# D1H.pdf register map
Vendor: Allwinner; Series: D1H.pdf; File version: 0.1
CPU: XuanTie C906 RISC-V CPU 0, little endian, MPU, FPU, double-precision FPU, 0 interrupt priority bits
Registers are 32-bit, read-write, reset 0x0 unless marked. A register's access mark holds for its fields unless they carry their own. Offsets are from the block's base; [hi:lo] are bit positions; {n}, {i} and the like mark numbered series; 'fields as' and 'values as' point back to an identical list.

## IOMMU
Base 0x02010000
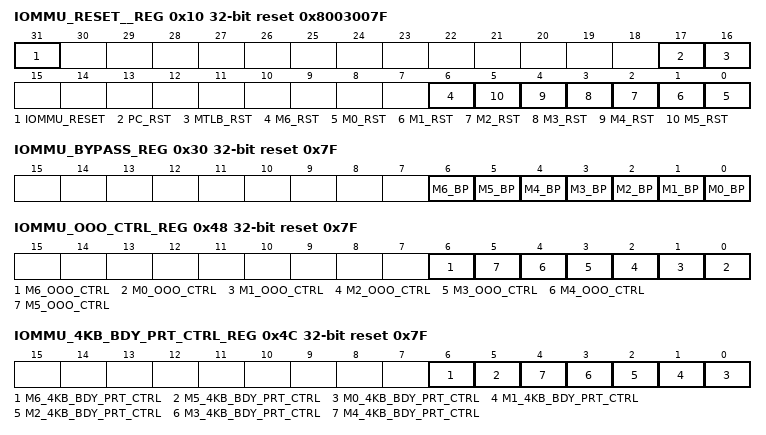
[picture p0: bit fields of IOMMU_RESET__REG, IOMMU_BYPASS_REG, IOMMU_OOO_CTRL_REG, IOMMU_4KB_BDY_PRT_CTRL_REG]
0x10 IOMMU_RESET__REG reset 0x8003007F
  [31] IOMMU_RESET — IOMMU Software Reset Switch 0: Set reset signal 1: Release reset signal Before IOMMU software reset operation, ensure IOMMU never be opened; or all bus operations are completed; or DRAM and the peripherals have opened the corresponding switch, for shielding the effects of IOMMU reset.
    0=Set (Set reset signal); 1=Release reset signal Before IOMMU software reset operation, ensure IOMMU never be opened; or all bus operations are completed; or DRAM and the peripherals have opened the corresponding switch, for shielding the effects of IOMMU reset
  [17] PC_RST — PTW Cache Reset PTW Cache address convert lane software reset switch. 0: Set reset signal 1: Release reset signal When PTW Cache occurs abnormal, the bit is used to reset PTW Cache individually.
    0=Set (Set reset signal); 1=Release reset signal When PTW Cache occurs abnormal, the bit is used to reset PTW Cache individually
  [16] MTLB_RST — Macrotlb Reset Macro TLB address convert lane software reset switch. 0: Set reset signal 1: Release reset signal When PTW Cache occurs abnormal, the bit is used to reset PTW Cache individually.
    values as PC_RST
  [6] M6_RST — Master6 Reset Master6 address convert lane software reset switch. 0: Set reset signal 1: Release reset signal When Master6 occurs abnormal, the bit is used to reset PTW Cache individually. Note: This bit is not used.
    0=Set (Set reset signal); 1=Release reset signal When Master6 occurs abnormal, the bit is used to reset PTW Cache individually. Note: This bit is not used.
  [n] M{n}_RST (n=0..5) — Master{n} Reset Master{n} address convert lane software reset switch. 0: Set reset signal 1: Release reset signal When Master{n} occurs abnormal, the bit is used to reset PTW Cache individually.
    0=Set (Set reset signal); 1=Release reset signal When Master{n} occurs abnormal, the bit is used to reset PTW Cache individually
0x20 IOMMU_ENABLE_REG — IOMMU Enable Register
  [0] ENABLE — IOMMU module enable switch 0: Disable IOMMU 1: Enable IOMMU Before IOMMU address mapping function opens, configure the Translation Table Base register; or ensure all masters are in bypass status or no the status of sending bus demand(such as reset)
    0=Disable IOMMU; 1=Enable IOMMU Before IOMMU address mapping function opens, configure the Translation Table Base register; or ensure all masters are in bypass status or no the status of sending bus demand(such as reset)
0x30 IOMMU_BYPASS_REG reset 0x7F — IOMMU Bypass Register
  [6] M6_BP — Master6 bypass switch After bypass function is opened, IOMMU can not map the address of Master6 sending, and directly output the virtual address to MBUS as physical address. 0: Disable bypass function 1: Enable bypass function Note: The bit is not used.
    0=Disable bypass function; 1=Enable bypass function Note: The bit is not used
  [n] M{n}_BP (n=1..5) — Master{n} bypass switch After bypass function is opened, IOMMU can not map the address of Master{n} sending, and directly output the virtual address to MBUS as physical address. 0: Disable bypass function 1: Enable bypass function
    0=Disable bypass function; 1=Enable bypass function
  [0] M0_BP — Master0 bypass switch After bypass function is opened, IOMMU can not map the address of Master0 sending, and directly output the virtual address to MBUS as physical address. 0: Disable bypass function 1: Enable bypass function Operating the register belongs to non-accurate timing sequence control function. That is, before the function is valid, master operation will complete address mapping function, and any subsequent operation will not perform address mapping. It is suggested that master is in reset state or in no any bus operation before operating the register.
    0=Disable bypass function; 1=Enable bypass function Operating the register belongs to non-accurate timing sequence control function. That is, before the function is valid, master operation will complete address mapping function, and any subsequent operation will not perform address mapping. It is suggested that master is in reset state or in no any bus operation before operating the register.
0x40 IOMMU_AUTO_GATING_REG reset 0x1 — IOMMU Auto Gating Register
  [0] IOMMU_AUTO_GATING — IOMMU circuit auto gating control The purpose is to decrease power consumption of the module. 0: Disable auto gating function 1: Enable auto gating function
    0=Disable auto gating function; 1=Enable auto gating function
0x44 IOMMU_WBUF_CTRL_REG reset 0x7F (reset mask 0x7F) — IOMMU Write Buffer Control Register
0x48 IOMMU_OOO_CTRL_REG reset 0x7F — IOMMU Out of Order Control Register
  [6] M6_OOO_CTRL — Master6 out-of-order control bit 0: Disable out-of-order 1: Enable out-of-order Note: This bit is not used.
    0=Disable out-of-order; 1=Enable out-of-order Note: This bit is not used
  [n] M{n}_OOO_CTRL (n=0..5) — Master{n} out-of-order control bit 0: Disable out-of-order 1: Enable out-of-order
    0=Disable out-of-order; 1=Enable out-of-order
0x4C IOMMU_4KB_BDY_PRT_CTRL_REG reset 0x7F — IOMMU 4KB Boundary Protect Control Register
  [6] M6_4KB_BDY_PRT_CTRL — Master6 4 KB boundary protect control bit 0: Disable 4 KB boundary protect 1: Enable 4 KB boundary protect Note: This bit is not used.
    0=Disable 4 KB boundary protect; 1=Enable 4 KB boundary protect Note: This bit is not used
  [5] M5_4KB_BDY_PRT_CTRL — Master4 4 KB boundary protect control bit 0: Disable 4 KB boundary protect 1: Enable 4 KB boundary protect
    0=Disable 4 KB boundary protect; 1=Enable 4 KB boundary protect
  [n] M{n}_4KB_BDY_PRT_CTRL (n=0..4) — Master{n} 4 KB boundary protect control bit 0: Disable 4 KB boundary protect 1: Enable 4 KB boundary protect
    values as M5_4KB_BDY_PRT_CTRL
0x50 IOMMU_TTB_REG — IOMMU Translation Table Base Register
  [31:14] TTB — Translation Table Base Level1 page table starting address, aligned to 16 KB. When operating the register, IOMMU address mapping function must be closed, namely IOMMU_ENABLE_REG is 0; Or Bypass function of all main equipment is set to 1, or no the state of transfer bus commands (such as setting).
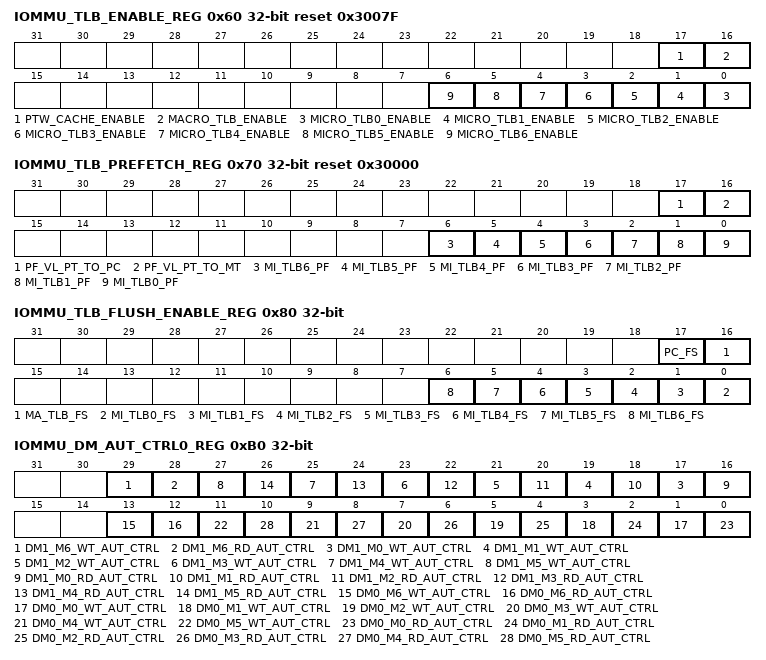
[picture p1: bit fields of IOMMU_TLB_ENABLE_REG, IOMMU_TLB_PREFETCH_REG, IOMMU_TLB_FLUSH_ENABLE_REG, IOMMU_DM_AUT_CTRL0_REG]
0x60 IOMMU_TLB_ENABLE_REG reset 0x3007F — IOMMU TLB Enable Register
  [all] fields
    0=Disable; 1=Enable
  [17] PTW_CACHE_ENABLE — PTW Cache enable bit 0: Disable 1: Enable
  [16] MACRO_TLB_ENABLE — Macro TLB enable bit 0: Disable 1: Enable
  [n] MICRO_TLB{n}_ENABLE (n=0..6) — Micro TLB{n} enable bit 0: Disable 1: Enable
0x70 IOMMU_TLB_PREFETCH_REG reset 0x30000 — IOMMU TLB Prefetch Register
  [17] PF_VL_PT_TO_PC — Prefetch Value Pagetable to PTW Cache 0: Disable 1: Enable If the function is enabled, the prefetch function will not update the invalid Level1 page table to PTW cache.
    0=Disable; 1=Enable If the function is enabled, the prefetch function will not update the invalid Level1 page table to PTW cache
  [16] PF_VL_PT_TO_MT — Prefetch Value Pagetable to Macro TLB 0: Disable 1: Enable If the function is enabled, the prefetch function will not update the invalid Level2 page table to Macro TLB.
    0=Disable; 1=Enable If the function is enabled, the prefetch function will not update the invalid Level2 page table to Macro TLB
  [6] MI_TLB6_PF — Micro TLB6 prefetch enable 0: Disable 1: Enable
    0=Disable; 1=Enable
  [5] MI_TLB5_PF — Micro TLB5 prefetch enable 0: Disable 1: Enable
    0=Disable; 1=Enable
  [4] MI_TLB4_PF — Micro TLB4 prefetch enable 0: Disable 1: Enable
    0=Disable; 1=Enable
  [3] MI_TLB3_PF — Micro TLB3 prefetch enable 0: Disable 1: Enable Note: If G2D accesses DDR, it is suggested that disable the prefetch function.
    0=Disable; 1=Enable Note: If G2D accesses DDR, it is suggested that disable the prefetch function
  [2] MI_TLB2_PF — Micro TLB2 prefetch enable 0: Disable 1: Enable
    0=Disable; 1=Enable
  [1] MI_TLB1_PF — Micro TLB1 prefetch enable 0: Disable 1: Enable
    0=Disable; 1=Enable
  [0] MI_TLB0_PF — Micro TLB0 prefetch enable 0: Disable 1: Enable
    0=Disable; 1=Enable
0x80 IOMMU_TLB_FLUSH_ENABLE_REG — IOMMU TLB Flush Enable Register
  [all] fields
    0=No clear operation or clear operation is completed; 1=Enable clear operation After the Flush operation is completed, the bit can clear automatically
  [17] PC_FS — PTW Cache Flush Clear PTW Cache 0: No clear operation or clear operation is completed 1: Enable clear operation After the Flush operation is completed, the bit can clear automatically.
  [16] MA_TLB_FS — Macro TLB Flush Clear Macro TLB 0: No clear operation or clear operation is completed 1: Enable clear operation After the Flush operation is completed, the bit can clear automatically.
  [n] MI_TLB{n}_FS (n=0..6) — Micro TLB{n} Flush Clear Micro TLB{n} 0: No clear operation or clear operation is completed 1: Enable clear operation After the Flush operation is completed, the bit can clear automatically.
0x84 IOMMU_TLB_IVLD_MODE_SEL_REG — IOMMU TLB Invalidation Mode Select Register
  [0] TLB_IVLD_MODE_SEL — 0: Invalidate TLB by using the Mask mode 1: Invalidate TLB by using the Start and End mode
    0=Invalidate TLB by using the Mask mode; 1=Invalidate TLB by using the Start and End mode
0x88 IOMMU_TLB_IVLD_STA_ADDR_REG — IOMMU TLB Invalidation Start Address Register
  [31:12] TLB_IVLD_STA_ADDR — TLB invalid start address, 4 KB aligned.
0x8C IOMMU_TLB_IVLD_END_ADDR_REG — IOMMU TLB Invalidation End Address Register
  [31:12] TLB_IVLD_END_ADDR — TLB invalid end address, 4 KB aligned.
0x90 IOMMU_TLB_IVLD_ADDR_REG — IOMMU TLB Invalidation Address Register
  [31:12] TLB_IVLD_ADDR — TLB invalid address, 4 KB aligned
0x94 IOMMU_TLB_IVLD_ADDR_MASK_REG — IOMMU TLB Invalidation Address Mask Register
  [31:12] TLB_IVLD_ADDR_MASK — TLB invalid address mask register, 4 KB aligned
0x98 IOMMU_TLB_IVLD_ENABLE_REG — IOMMU TLB Invalidation Enable Register
  [0] TLB_IVLD_ENABLE — Enable TLB invalidation operation 0: No operation or operation is completed 1: Enable invalidation operation After invalidation operation is completed, the bit can clear automatically. When operating invalidation operation, TLB/Cache operation has not affected. After or before invalidation operation starts, there is no absolute relationship between the same address switch operation and invalidation operation.
    0=No operation or operation is completed; 1=Enable invalidation operation After invalidation operation is completed, the bit can clear automatically. When operating invalidation operation, TLB/Cache operation has not affected. After or before invalidation operation starts, there is no absolute relationship between the same address switch operation and invalidation operation.
0x9C IOMMU_PC_IVLD_MODE_SEL_REG — IOMMU PC Invalidation Mode Select Register
  [0] PC_IVLD_MODE_SEL — PTW Cache Invalid Mode Select 0: Invalidate PTW by using the Mask mode 1: Invalidate PTW by using the Start and End mode
    0=Invalidate PTW by using the Mask mode; 1=Invalidate PTW by using the Start and End mode
0xA0 IOMMU_PC_IVLD_ADDR_REG — IOMMU PC Invalidation Address Register
  [31:20] PC_IVLD_ADDR — PTW Cache invalid address, 1 MB aligned.
0xA4 IOMMU_PC_IVLD_STA_ADDR_REG — IOMMU PC Invalidation Start Address Register
  [31:20] PC_IVLD_SA — PTW Cache invalid start address, 1 MB aligned.
0xA8 IOMMU_PC_IVLD_ENABLE_REG — IOMMU PC Invalidation Enable Register
  [0] PC_IVLD_ENABLE — Enable PTW Cache invalidation operation 0: No operation or operation is completed 1: Enable invalidation operation After invalidation operation is completed, the bit can clear automatically. After or before invalidation operation starts, there is no absolute relationship between the same address switch operation and invalidation operation.
    0=No operation or operation is completed; 1=Enable invalidation operation After invalidation operation is completed, the bit can clear automatically. After or before invalidation operation starts, there is no absolute relationship between the same address switch operation and invalidation operation.
0xAC IOMMU_PC_IVLD_END_ADDR_REG — IOMMU PC Invalidation End Address Register
  [31:20] PC_IVLD_EA — PTW Cache invalid end address, 1 MB aligned.
0xB0 IOMMU_DM_AUT_CTRL0_REG — IOMMU Domain Authority Control 0 Register
  [29] DM1_M6_WT_AUT_CTRL — Domain1 write permission control for master6 0: The write-operation is permitted 1: The write-operation is prohibited Note: The bit is not used.
    0=permitted (The write-operation is permitted); 1=prohibited (The write-operation is prohibited Note: The bit is not used.)
  [28] DM1_M6_RD_AUT_CTRL — Domain1 read permission control for master6 0: The read-operation is permitted 1: The read-operation is prohibited Note: The bit is not used.
    0=permitted (The read-operation is permitted); 1=prohibited (The read-operation is prohibited Note: The bit is not used.)
  [2n+17] DM1_M{n}_WT_AUT_CTRL (n=0..5) — Domain1 write permission control for master{n} 0: The write-operation is permitted 1: The write-operation is prohibited
    0=permitted (The write-operation is permitted); 1=prohibited (The write-operation is prohibited)
  [2n+16] DM1_M{n}_RD_AUT_CTRL (n=0..5) — Domain1 read permission control for master{n} 0: The read-operation is permitted 1: The read-operation is prohibited
    0=permitted (The read-operation is permitted); 1=prohibited (The read-operation is prohibited)
  [13] DM0_M6_WT_AUT_CTRL ro — Domain0 write permission control for master6 0: The write-operation is permitted 1: The write-operation is prohibited Note: The bit is not used.
    values as DM1_M6_WT_AUT_CTRL
  [12] DM0_M6_RD_AUT_CTRL ro — Domain0 read permission control for master6 0: The read-operation is permitted 1: The read-operation is prohibited Note: The bit is not used.
    values as DM1_M6_RD_AUT_CTRL
  [2n+1] DM0_M{n}_WT_AUT_CTRL ro (n=0..5) — Domain0 write permission control for master{n} 0: The write-operation is permitted 1: The write-operation is prohibited
    values as DM1_M0_WT_AUT_CTRL
  [2n] DM0_M{n}_RD_AUT_CTRL ro (n=0..5) — Domain0 read permission control for master{n} 0: The read-operation is permitted 1: The read-operation is prohibited
    values as DM1_M0_RD_AUT_CTRL
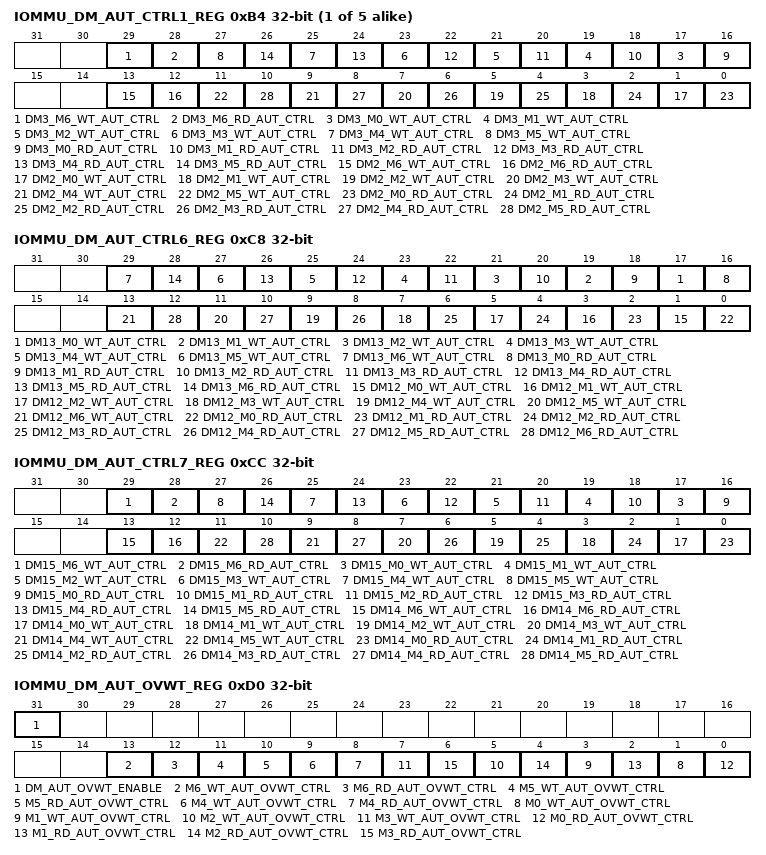
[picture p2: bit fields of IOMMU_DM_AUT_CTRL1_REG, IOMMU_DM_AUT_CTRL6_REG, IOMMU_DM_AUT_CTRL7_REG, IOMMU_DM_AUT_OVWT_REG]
{0xB0+4i} IOMMU_DM_AUT_CTRL{i}_REG (i=1..5) — IOMMU Domain Authority Control {i} Register
  [29] DM{2i+1}_M6_WT_AUT_CTRL — Domain{2i+1} write permission control for master6 0: The write-operation is permitted 1: The write-operation is prohibited Note: The bit is not used.
    values as IOMMU_DM_AUT_CTRL0_REG.DM1_M6_WT_AUT_CTRL
  [28] DM{2i+1}_M6_RD_AUT_CTRL — Domain{2i+1} read permission control for master6 0: The read-operation is permitted 1: The read-operation is prohibited Note: The bit is not used.
    values as IOMMU_DM_AUT_CTRL0_REG.DM1_M6_RD_AUT_CTRL
  [2n+17] DM{2i+1}_M{n}_WT_AUT_CTRL (n=0..5) — Domain{2i+1} write permission control for master{n} 0: The write-operation is permitted 1: The write-operation is prohibited
    values as IOMMU_DM_AUT_CTRL0_REG.DM1_M0_WT_AUT_CTRL
  [2n+16] DM{2i+1}_M{n}_RD_AUT_CTRL (n=0..5) — Domain{2i+1} read permission control for master{n} 0: The read-operation is permitted 1: The read-operation is prohibited
    values as IOMMU_DM_AUT_CTRL0_REG.DM1_M0_RD_AUT_CTRL
  [13] DM{2i}_M6_WT_AUT_CTRL — Domain{2i} write permission control for master6 0: The write-operation is permitted 1: The write-operation is prohibited Note: The bit is not used.
    values as IOMMU_DM_AUT_CTRL0_REG.DM1_M6_WT_AUT_CTRL
  [12] DM{2i}_M6_RD_AUT_CTRL — Domain{2i} read permission control for master6 0: The read-operation is permitted 1: The read-operation is prohibited Note: The bit is not used.
    values as IOMMU_DM_AUT_CTRL0_REG.DM1_M6_RD_AUT_CTRL
  [2n+1] DM{2i}_M{n}_WT_AUT_CTRL (n=0..5) — Domain{2i} write permission control for master{n} 0: The write-operation is permitted 1: The write-operation is prohibited
    values as IOMMU_DM_AUT_CTRL0_REG.DM1_M0_WT_AUT_CTRL
  [2n] DM{2i}_M{n}_RD_AUT_CTRL (n=0..5) — Domain{2i} read permission control for master{n} 0: The read-operation is permitted 1: The read-operation is prohibited
    values as IOMMU_DM_AUT_CTRL0_REG.DM1_M0_RD_AUT_CTRL
0xC8 IOMMU_DM_AUT_CTRL6_REG — IOMMU Domain Authority Control 6 Register
  [2n+17] DM13_M{n}_WT_AUT_CTRL (n=0..6) — Domain13 write permission control for master{n} 0: The write-operation is permitted 1: The write-operation is prohibited
    values as IOMMU_DM_AUT_CTRL0_REG.DM1_M0_WT_AUT_CTRL
  [2n+16] DM13_M{n}_RD_AUT_CTRL (n=0..6) — Domain13 read permission control for master{n} 0: The read-operation is permitted 1: The read-operation is prohibited
    values as IOMMU_DM_AUT_CTRL0_REG.DM1_M0_RD_AUT_CTRL
  [2n+1] DM12_M{n}_WT_AUT_CTRL (n=0..6) — Domain12 write permission control for master{n} 0: The write-operation is permitted 1: The write-operation is prohibited
    values as IOMMU_DM_AUT_CTRL0_REG.DM1_M0_WT_AUT_CTRL
  [2n] DM12_M{n}_RD_AUT_CTRL (n=0..6) — Domain12 read permission control for master{n} 0: The read-operation is permitted 1: The read-operation is prohibited
    values as IOMMU_DM_AUT_CTRL0_REG.DM1_M0_RD_AUT_CTRL
0xCC IOMMU_DM_AUT_CTRL7_REG — IOMMU Domain Authority Control 7 Register
  [29] DM15_M6_WT_AUT_CTRL — Domain15 write permission control for master6 0: The write-operation is permitted 1: The write-operation is prohibited Note: The bit is not used.
    values as IOMMU_DM_AUT_CTRL0_REG.DM1_M6_WT_AUT_CTRL
  [28] DM15_M6_RD_AUT_CTRL — Domain15 read permission control for master6 0: The read-operation is permitted 1: The read-operation is prohibited Note: The bit is not used.
    values as IOMMU_DM_AUT_CTRL0_REG.DM1_M6_RD_AUT_CTRL
  [2n+17] DM15_M{n}_WT_AUT_CTRL (n=0..5) — Domain15 write permission control for master{n} 0: The write-operation is permitted 1: The write-operation is prohibited
    values as IOMMU_DM_AUT_CTRL0_REG.DM1_M0_WT_AUT_CTRL
  [2n+16] DM15_M{n}_RD_AUT_CTRL (n=0..5) — Domain15 read permission control for master{n} 0: The read-operation is permitted 1: The read-operation is prohibited
    values as IOMMU_DM_AUT_CTRL0_REG.DM1_M0_RD_AUT_CTRL
  [13] DM14_M6_WT_AUT_CTRL — Domain14 write permission control for master6 0: The write-operation is permitted 1: The write-operation is prohibited Note: The bit is not used.
    values as IOMMU_DM_AUT_CTRL0_REG.DM1_M6_WT_AUT_CTRL
  [12] DM14_M6_RD_AUT_CTRL — Domain14 read permission control for master6 0: The read-operation is permitted 1: The read-operation is prohibited Note: The bit is not used.
    values as IOMMU_DM_AUT_CTRL0_REG.DM1_M6_RD_AUT_CTRL
  [2n+1] DM14_M{n}_WT_AUT_CTRL (n=0..5) — Domain14 write permission control for master{n} 0: The write-operation is permitted 1: The write-operation is prohibited
    values as IOMMU_DM_AUT_CTRL0_REG.DM1_M0_WT_AUT_CTRL
  [2n] DM14_M{n}_RD_AUT_CTRL (n=0..5) — Domain14 read permission control for master{n} 0: The read-operation is permitted 1: The read-operation is prohibited
    values as IOMMU_DM_AUT_CTRL0_REG.DM1_M0_RD_AUT_CTRL
0xD0 IOMMU_DM_AUT_OVWT_REG — IOMMU Domain Authority Overwrite Register
  [31] DM_AUT_OVWT_ENABLE — Domain write/read permission overwrite enable 0: Disable 1: Enable
    0=Disable; 1=Enable
  [13] M6_WT_AUT_OVWT_CTRL — Master6 write permission overwrite control 0: The write-operation is permitted 1: The write-operation is prohibited Note: The bit is not used.
    values as IOMMU_DM_AUT_CTRL0_REG.DM1_M6_WT_AUT_CTRL
  [12] M6_RD_AUT_OVWT_CTRL — Master6 read permission overwrite control 0: The read-operation is permitted 1: The read-operation is prohibited Note: The bit is not used.
    values as IOMMU_DM_AUT_CTRL0_REG.DM1_M6_RD_AUT_CTRL
  [11] M5_WT_AUT_OVWT_CTRL — Master5 write permission overwrite control 0: The write-operation is permitted 1: The write-operation is prohibited
    values as IOMMU_DM_AUT_CTRL0_REG.DM1_M0_WT_AUT_CTRL
  [10] M5_RD_AUT_OVWT_CTRL — Master5 read permission overwrite control 0: The read-operation is permitted 1: The read-operation is prohibited
    values as IOMMU_DM_AUT_CTRL0_REG.DM1_M0_RD_AUT_CTRL
  [9] M4_WT_AUT_OVWT_CTRL — Master5 write permission overwrite control 0: The write-operation is permitted 1: The write-operation is prohibited
    values as IOMMU_DM_AUT_CTRL0_REG.DM1_M0_WT_AUT_CTRL
  [8] M4_RD_AUT_OVWT_CTRL — Master5 read permission overwrite control 0: The read-operation is permitted 1: The read-operation is prohibited
    values as IOMMU_DM_AUT_CTRL0_REG.DM1_M0_RD_AUT_CTRL
  [2n+1] M{n}_WT_AUT_OVWT_CTRL (n=0..3) — Master{n} write permission overwrite control 0: The write-operation is permitted 1: The write-operation is prohibited
    values as IOMMU_DM_AUT_CTRL0_REG.DM1_M0_WT_AUT_CTRL
  [2n] M{n}_RD_AUT_OVWT_CTRL (n=0..3) — Master{n} read permission overwrite control 0: The read-operation is permitted 1: The read-operation is prohibited
    values as IOMMU_DM_AUT_CTRL0_REG.DM1_M0_RD_AUT_CTRL
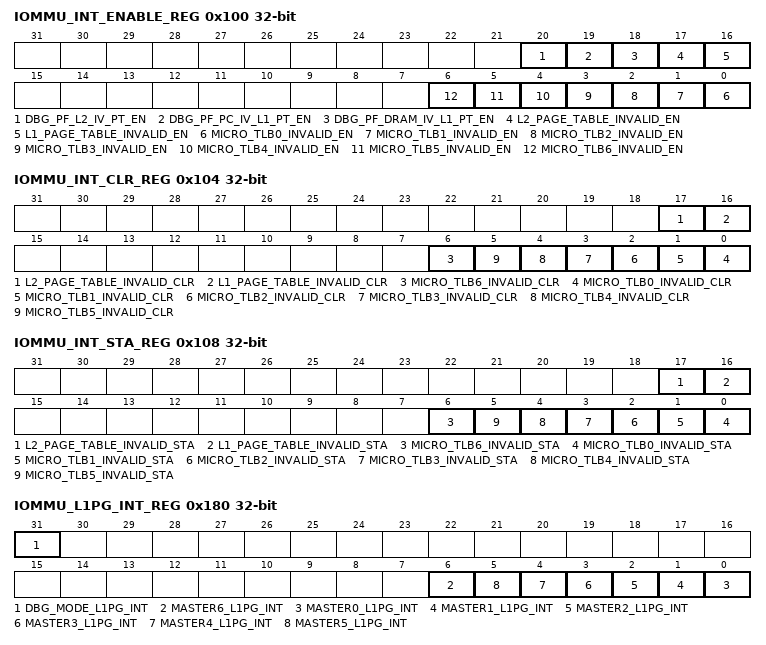
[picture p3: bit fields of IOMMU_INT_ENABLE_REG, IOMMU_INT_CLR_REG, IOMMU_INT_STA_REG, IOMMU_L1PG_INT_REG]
0x100 IOMMU_INT_ENABLE_REG — IOMMU Interrupt Enable Register
  [all] fields
    0=Mask interrupt; 1=Enable interrupt
  [20] DBG_PF_L2_IV_PT_EN — Debug or Prefetch Invalid Page Table Enable 0: Mask interrupt 1: Enable interrupt
  [19] DBG_PF_PC_IV_L1_PT_EN — Debug or Prefetch PTW Cache Invalid Level1 Page Table Enable 0: Mask interrupt 1: Enable interrupt
  [18] DBG_PF_DRAM_IV_L1_PT_EN — Debug or Prefetch DRAM Invalid Level1 Page Table Enable 0: Mask interrupt 1: Enable interrupt
  [17] L2_PAGE_TABLE_INVALID_EN — Level2 page table invalid interrupt enable 0: Mask interrupt 1: Enable interrupt
  [16] L1_PAGE_TABLE_INVALID_EN — Level1 page table invalid interrupt enable 0: Mask interrupt 1: Enable interrupt
  [n] MICRO_TLB{n}_INVALID_EN (n=0..6) — Micro TLB{n} permission invalid interrupt enable 0: Mask interrupt 1: Enable interrupt
0x104 IOMMU_INT_CLR_REG — IOMMU Interrupt Clear Register
  [17] L2_PAGE_TABLE_INVALID_CLR wo — Level2 page table invalid interrupt clear bit 0: Invalid operation 1: Clear interrupt
    0=Invalid operation; 1=Clear interrupt
  [16] L1_PAGE_TABLE_INVALID_CLR wo — Level1 page table invalid interrupt clear bit 0: Invalid operation 1: Clear interrupt
    0=Invalid operation; 1=Clear interrupt
  [6] MICRO_TLB6_INVALID_CLR wo — Micro TLB6 permission invalid interrupt clear bit 0: Invalid operation 1: Clear interrupt Note: The bit is not used.
    0=Invalid operation; 1=Clear interrupt Note: The bit is not used
  [n] MICRO_TLB{n}_INVALID_CLR wo (n=0..5) — Micro TLB{n} permission invalid interrupt clear bit 0: Invalid operation 1: Clear interrupt
    0=Invalid operation; 1=Clear interrupt
0x108 IOMMU_INT_STA_REG — IOMMU Interrupt Status Register
  [17] L2_PAGE_TABLE_INVALID_STA ro — Level2 page table invalid interrupt status bit 0: Interrupt does not happen or interrupt is cleared 1: Interrupt happens
    0=Interrupt does not happen or interrupt is cleared; 1=Interrupt_happens
  [16] L1_PAGE_TABLE_INVALID_STA ro — Level1 page table invalid interrupt status bit 0: Interrupt does not happen or interrupt is cleared 1: Interrupt happens
    values as L2_PAGE_TABLE_INVALID_STA
  [6] MICRO_TLB6_INVALID_STA ro — Micro TLB6 permission invalid interrupt status bit 0: Interrupt does not happen or interrupt is cleared 1: Interrupt happens Note: The bit is not used.
    0=Interrupt does not happen or interrupt is cleared; 1=Interrupt happens Note: The bit is not used
  [n] MICRO_TLB{n}_INVALID_STA ro (n=0..5) — Micro TLB{n} permission invalid interrupt status bit 0: Interrupt does not happen or interrupt is cleared 1: Interrupt happens
    values as L2_PAGE_TABLE_INVALID_STA
{0x110+4i} IOMMU_INT_ERR_ADDR{i}_REG (i=0..6) — IOMMU Interrupt Error Address {i} Register
  [31:0] INT_ERR_ADDR{i} ro — Virtual address that caused Micro TLB{i} to interrupt
0x130 IOMMU_INT_ERR_ADDR7_REG — IOMMU Interrupt Error Address 7 Register
  [31:0] INT_ERR_ADDR7 ro — Virtual address that caused L1 page table to interrupt
0x134 IOMMU_INT_ERR_ADDR8_REG — IOMMU Interrupt Error Address 8 Register
  [31:0] INT_ERR_ADDR8 ro — Virtual address that caused L2 page table to interrupt
{0x150+4i} IOMMU_INT_ERR_DATA{i}_REG (i=0..5) — IOMMU Interrupt Error Data {i} Register
  [31:0] INT_ERR_DATA{i} ro — Corresponding page table of virtual address that caused Micro TLB{i} to interrupt
0x168 IOMMU_INT_ERR_DATA6_REG — IOMMU Interrupt Error Data 6 Register
  [31:0] INT_ERR_DATA6 ro — Corresponding page table of virtual address that caused Micro TLB6 to interrupt Note: This field is not used.
0x170 IOMMU_INT_ERR_DATA7_REG — IOMMU Interrupt Error Data 7 Register
  [31:0] INT_ERR_DATA7 ro — Corresponding page table of virtual address that caused L1 page table to interrupt
0x174 IOMMU_INT_ERR_DATA8_REG — IOMMU Interrupt Error Data 8 Register
  [31:0] INT_ERR_DATA8 ro — Corresponding page table of virtual address that caused L2 page table to interrupt
0x180 IOMMU_L1PG_INT_REG — IOMMU L1 Page Table Interrupt Register
  [31] DBG_MODE_L1PG_INT ro — Debug mode address switch causes L1 page table to occur interrupt.
  [6] MASTER6_L1PG_INT ro — Master6 address switch causes L1 page table to occur interrupt. Note: The bit is not used.
  [n] MASTER{n}_L1PG_INT ro (n=0..5) — Master{n} address switch causes L1 page table to occur interrupt.
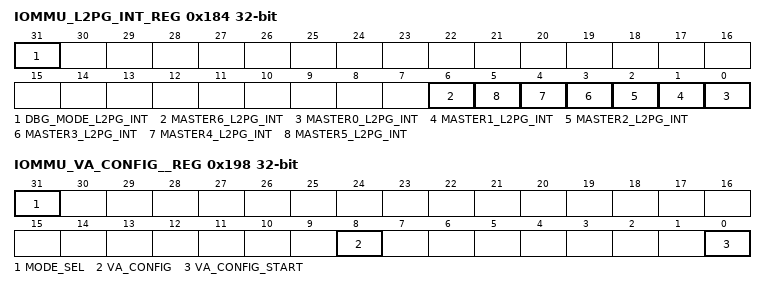
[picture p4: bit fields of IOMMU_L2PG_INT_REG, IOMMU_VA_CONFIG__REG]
0x184 IOMMU_L2PG_INT_REG — IOMMU L2 Page Table Interrupt Register
  [31] DBG_MODE_L2PG_INT ro — Debug mode address switch causes L2 page table to occur interrupt.
  [6] MASTER6_L2PG_INT ro — Master6 address switch causes L2 page table to occur interrupt. Note: The bit is not used.
  [n] MASTER{n}_L2PG_INT ro (n=0..5) — Master{n} address switch causes L2 page table to occur interrupt.
0x190 IOMMU_VA__REG
  [31:0] VA — Virtual address of read/write
0x194 IOMMU_VA_DATA__REG
  [31:0] VA_DATA — Data corresponding to read/write virtual address
0x198 IOMMU_VA_CONFIG__REG
  [31] MODE_SEL — 0: Prefetch 1: Debug Mode It is used to chose prefetch mode or Debug mode.
    0=Prefetch; 1=Debug Mode It is used to chose prefetch mode or Debug mode
  [8] VA_CONFIG — Virtual Address Configuration 0: Read operation 1: Write operation
    0=Read operation; 1=Write operation
  [0] VA_CONFIG_START — 0: No operation or operation is completed 1: Start After the operation is completed, the bit can clear automatically. Read operation process: a) Write IOMMU_VA_REG[31:0]; b) Write IOMMU_VA_CONFIG_REG[8] to 0; c) Write IOMMU_VA_CONFIG_REG[0] to 1 to start read-process; d) Query IOMMU_VA_CONFIG_REG[0] until it is 0; e) Read IOMMU_VA_DATA_REG[31:0]; Write operation process: a) Write IOMMU_VA_REG[31:0]; b) Write IOMMU_VA_DATA_REG[31:0]; c) Write IOMMU_VA_CONFIG_REG[8] to 1; d) Write IOMMU_VA_CONFIG_REG[0] to 1 to start write-process; e) Query IOMMU_VA_CONFIG_REG[0] until it is 0;
    0=No operation or operation is completed; 1=Start After the operation is completed, the bit can clear automatically. Read operation process: a) Write IOMMU_VA_REG[31:0]; b) Write IOMMU_VA_CONFIG_REG[8] to 0; c) Write IOMMU_VA_CONFIG_REG[0] to 1 to start read-process; d) Query IOMMU_VA_CONFIG_REG[0] until it is 0; e) Read IOMMU_VA_DATA_REG[31:0]; Write operation process: a) Write IOMMU_VA_REG[31:0]; b) Write IOMMU_VA_DATA_REG[31:0]; c) Write IOMMU_VA_CONFIG_REG[8] to 1; d) Write IOMMU_VA_CONFIG_REG[0] to 1 to start write-process; e) Query IOMMU_VA_CONFIG_REG[0] until it is 0;
0x200 IOMMU_PMU_ENABLE__REG
  [0] PMU_ENABLE — 0: Disable statistical function 1: Enable statistical function
    0=Disable statistical function; 1=Enable statistical function
0x210 IOMMU_PMU_CLR__REG
  [0] PMU_CLR — 0: No clear operation or clear operation is completed 1: Clear counter data After the operation is completed, the bit can clear automatically.
    0=No clear operation or clear operation is completed; 1=Clear counter data After the operation is completed, the bit can clear automatically
{0x230+0x10*i} IOMMU_PMU_ACCESS_LOW{i}_REG (i=0..5) — IOMMU PMU Access Low {i} Register
  [31:0] PMU_ACCESS_LOW{i} ro — Record total number of Micro TLB{i} access, lower 32-bit register
{0x234+0x10*i} IOMMU_PMU_ACCESS_HIGH{i}_REG (i=0..5) — IOMMU PMU Access High {i} Register
  [10:0] PMU_ACCESS_HIGH{i} ro — Record total number of Micro TLB{i} access, higher 11-bit register
{0x238+0x10*i} IOMMU_PMU_HIT_LOW{i}_REG (i=0..5) — IOMMU PMU Hit Low {i} Register
  [31:0] PMU_HIT_LOW{i} ro — Record total number of Micro TLB{i} hit, lower 32-bit register
{0x23C+0x10*i} IOMMU_PMU_HIT_HIGH{i}_REG (i=0..5) — IOMMU PMU Hit High {i} Register
  [10:0] PMU_HIT_HIGH{i} ro — Record total number of Micro TLB{i} hit, higher 11-bit register
0x290 IOMMU_PMU_ACCESS_LOW6_REG — IOMMU PMU Access Low 6 Register
  [31:0] PMU_ACCESS_LOW6 ro — Record total number of Micro TLB6 access, lower 32-bit register Note: The field is not used.
0x294 IOMMU_PMU_ACCESS_HIGH6_REG — IOMMU PMU Access High 6 Register
  [10:0] PMU_ACCESS_HIGH6 ro — Record total number of Micro TLB6 access, higher 11-bit register Note: The field is not used.
0x298 IOMMU_PMU_HIT_LOW6_REG — IOMMU PMU Hit Low 6 Register
  [31:0] PMU_HIT_LOW6 ro — Record total number of Micro TLB6 hit, lower 32-bit register Note: The field is not used.
0x29C IOMMU_PMU_HIT_HIGH6_REG — IOMMU PMU Hit High 6 Register
  [10:0] PMU_HIT_HIGH6 ro — Record total number of Micro TLB6 hit, higher 11-bit register Note: The field is not used.
0x2D0 IOMMU_PMU_ACCESS_LOW7_REG — IOMMU PMU Access Low 7 Register
  [31:0] PMU_ACCESS_LOW7 ro — Record total number of Micro TLB7 access, lower 32-bit register
0x2D4 IOMMU_PMU_ACCESS_HIGH7_REG — IOMMU PMU Access High 7 Register
  [10:0] PMU_ACCESS_HIGH7 ro — Record total number of Micro TLB7 access, higher 11-bit register
0x2D8 IOMMU_PMU_HIT_LOW7_REG — IOMMU PMU Hit Low 7 Register
  [31:0] PMU_HIT_LOW7 ro — Record total number of Micro TLB7 hit, lower 32-bit register
0x2DC IOMMU_PMU_HIT_HIGH7_REG — IOMMU PMU Hit High 7 Register
  [10:0] PMU_HIT_HIGH7 ro — Record total number of Micro TLB7 hit, higher 11-bit register
0x2E0 IOMMU_PMU_ACCESS_LOW8_REG — IOMMU PMU Access Low 8 Register
  [31:0] PMU_ACCESS_LOW8 ro — Record total number of PTW Cache access, lower 32-bit register
0x2E4 IOMMU_PMU_ACCESS_HIGH8_REG — IOMMU PMU Access High 8 Register
  [10:0] PMU_ACCESS_HIGH8 ro — Record total number of PTW Cache access, higher 11-bit register
0x2E8 IOMMU_PMU_HIT_LOW8_REG — IOMMU PMU Hit Low 8 Register
  [31:0] PMU_HIT_LOW8 ro — Record total number of PTW Cache hit, lower 32-bit register
0x2EC IOMMU_PMU_HIT_HIGH8_REG — IOMMU PMU Hit High 8 Register
  [10:0] PMU_HIT_HIGH8 ro — Record total number of PTW Cache hit, higher 11-bit register
{0x300+0x10*i} IOMMU_PMU_TL_LOW{i}_REG (i=0..5) — IOMMU Total Latency Low {i} Register
  [31:0] PMU_TL_LOW{i} ro — Record total latency of Master{i}, lower 32-bit register
{0x304+0x10*i} IOMMU_PMU_TL_HIGH{i}_REG (i=0..5) — IOMMU Total Latency High {i} Register
  [17:0] PMU_TL_HIGH{i} ro — Record total latency of Master{i}, higher 18-bit register
{0x308+0x10*i} IOMMU_PMU_ML{i}_REG (i=0..5) — IOMMU Max Latency {i} Register
  [31:0] PMU_ML{i} ro — Record the max latency of Master{i}.
0x360 IOMMU_PMU_TL_LOW6_REG — IOMMU Total Latency Low 6 Register
  [31:0] PMU_TL_LOW6 ro — Record total latency of Master6, lower 32-bit register Note: The field is not used.
0x364 IOMMU_PMU_TL_HIGH6_REG — IOMMU Total Latency High 6 Register
  [17:0] PMU_TL_HIGH6 ro — Record total latency of Master6, higher 18-bit register Note: The field is not used.
0x368 IOMMU_PMU_ML6_REG — IOMMU Max Latency 6 Register
  [31:0] PMU_ML6 ro — Record the max latency of Master6. Note: The field is not used.
